 VERSION ""

NS_ :

BS_:

BU_: BMS VCU

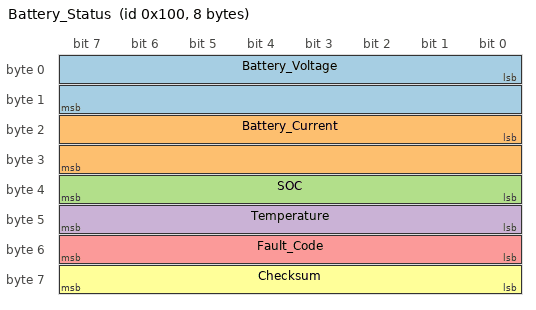
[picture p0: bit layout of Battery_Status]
BO_ 256 Battery_Status: 8 BMS
 SG_ Battery_Voltage : 0|16@1+ (0.1,0) [0|6553.5] "V" VCU
 SG_ Battery_Current : 16|16@1- (0.1,-3276.8) [-3276.8|3276.7] "A" VCU
 SG_ SOC : 32|8@1+ (1,0) [0|100] "%" VCU
 SG_ Temperature : 40|8@1+ (1,-40) [-40|215] "degC" VCU
 SG_ Fault_Code : 48|8@1+ (1,0) [0|255] "" VCU
 SG_ Checksum : 56|8@1+ (1,0) [0|255] "" VCU

CM_ BO_ 256 "Battery status message from BMS to VCU";
CM_ SG_ 256 Battery_Voltage "Total battery pack voltage";
CM_ SG_ 256 Battery_Current "Negative = discharging, positive = charging";
CM_ SG_ 256 SOC "State of Charge percentage";
CM_ SG_ 256 Temperature "Average battery temperature";
CM_ SG_ 256 Fault_Code "0 = OK, 1 = Overvoltage, 2 = Undervoltage, 3 = Overtemp";
